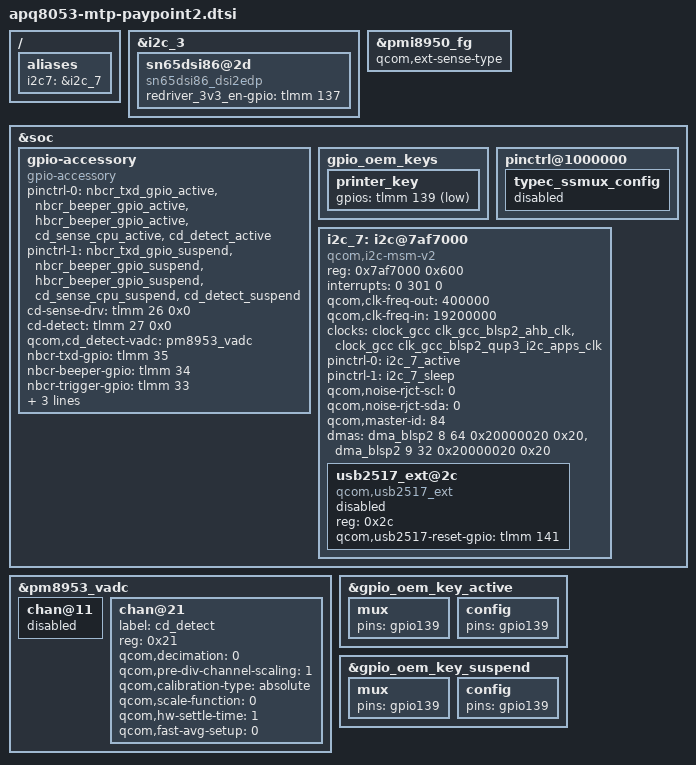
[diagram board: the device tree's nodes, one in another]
/*
 * Copyright (c) 2015-2016, The Linux Foundation. All rights reserved.
 *
 * This program is free software; you can redistribute it and/or modify
 * it under the terms of the GNU General Public License version 2 and
 * only version 2 as published by the Free Software Foundation.
 *
 * This program is distributed in the hope that it will be useful,
 * but WITHOUT ANY WARRANTY; without even the implied warranty of
 * MERCHANTABILITY or FITNESS FOR A PARTICULAR PURPOSE.  See the
 * GNU General Public License for more details.
 */
/ {
	aliases {
		i2c7 = &i2c_7;
	};
};

/*Leo Guo add for Puck to support HPD for DP panel*/
&i2c_3 {
	sn65dsi86@2d {
		compatible = "sn65dsi86_dsi2edp";
		redriver_3v3_en-gpio = <&tlmm 137 0>;
	};
};

&pmi8950_fg {
	/* use external rsense for parallel charging */
	qcom,ext-sense-type;
};


&soc {
	/*salyer add for peripheral */
	gpio-accessory{
		compatible = "gpio-accessory";
		pinctrl-names = "gpio_accessory_active","gpio_accessory_suspend";
		pinctrl-0 = <&nbcr_txd_gpio_active &nbcr_beeper_gpio_active &hbcr_beeper_gpio_active
				&cd_sense_cpu_active &cd_detect_active>;
		pinctrl-1 = <&nbcr_txd_gpio_suspend &nbcr_beeper_gpio_suspend &hbcr_beeper_gpio_suspend
 				&cd_sense_cpu_suspend &cd_detect_suspend>;

		/* Cash-Drawer GPIO */
		//cd-solenoid-en = <&tlmm 25 0x0>;
		cd-sense-drv = <&tlmm 26 0x0>;
		cd-detect = <&tlmm 27 0x0>;
		qcom,cd_detect-vadc = <&pm8953_vadc>;
		/* Cash-Drawer GPIO */

		/* Barcode reader GPIO */
		nbcr-txd-gpio = <&tlmm 35 0x0>;
		nbcr-beeper-gpio = <&tlmm 34 0x0>;
		nbcr-trigger-gpio = <&tlmm 33 0x0>;
		hbcr-beeper-gpio = <&tlmm 130 0x0>;
		hbcr-trigger-gpio = <&tlmm 131 0x0>;
		/* Barcode reader GPIO */

		/* enable printer 24v GPIO */
		pp-power-en = <&tlmm 28 0x0>;
		/* enable printer 24v GPIO */
		status = "okay";
	};

	/* 20170316, Adil.Zhu, moidify printer-key gpio for paypoint 2.0 */
	gpio_oem_keys {
		printer_key {
			gpios = <&tlmm 139 0x1>;
		};
	};

	pinctrl@1000000 {
		typec_ssmux_config {
			status = "disabled";
		};
	};

	/*2017-04-22 Jack W Lu: Add I2C_7 interface for external HUB2.0 SMBUS {*/
	i2c_7: i2c@7af7000 { /* BLSP2 QUP2 */
		compatible = "qcom,i2c-msm-v2";
		#address-cells = <1>;
		#size-cells = <0>;
		reg-names = "qup_phys_addr";
		reg = <0x7af7000 0x600>;
		interrupt-names = "qup_irq";
		interrupts = <0 301 0>;
		qcom,clk-freq-out = <400000>;
		qcom,clk-freq-in  = <19200000>;
		clock-names = "iface_clk", "core_clk";
		clocks = <&clock_gcc clk_gcc_blsp2_ahb_clk>,
			<&clock_gcc clk_gcc_blsp2_qup3_i2c_apps_clk>;

		pinctrl-names = "i2c_active", "i2c_sleep";
		pinctrl-0 = <&i2c_7_active>;
		pinctrl-1 = <&i2c_7_sleep>;
		qcom,noise-rjct-scl = <0>;
		qcom,noise-rjct-sda = <0>;
		qcom,master-id = <84>;
		dmas = <&dma_blsp2 8 64 0x20000020 0x20>,
			<&dma_blsp2 9 32 0x20000020 0x20>;
		dma-names = "tx", "rx";
		status = "okay";

		/*ONLY PP2.0 EVT2 use this setting*/
		usb2517_ext@2c {
			compatible = "qcom,usb2517_ext";
			reg = <0x2c>;
			qcom,usb2517-reset-gpio = <&tlmm 141 0>;/*Reserve_GPIO6: for external HUB2.0 usb2517 reset pin*/
			status = "disabled";/*ONLY PP2.0 EVT2 use this setting*/
		};
	};
	/*2017-04-22 Jack W Lu: Add I2C_7 interface for external HUB2.0 SMBUS }*/
};


&pm8953_vadc {
	chan@11 {
		status ="disabled";
	};

	/*pp,tony.l.cai,20170214,adc pin reserved for cd_detect{*/
	chan@21 {
		label = "cd_detect";
		reg = <0x21>;
		qcom,decimation = <0>;
		qcom,pre-div-channel-scaling = <1>; //1/3
		qcom,calibration-type = "absolute";
		qcom,scale-function = <0>;
		qcom,hw-settle-time = <1>; //1: Setting a delay of 100us is recommended for MPP channels.
		qcom,fast-avg-setup = <0>;
	};
	/*}pp,tony.l.cai,20170214,adc pin reserved for cd_detect*/
};

&gpio_oem_key_active{
    mux {
            pins = "gpio139";
        };

    config {
            pins =  "gpio139";
        };
};

&gpio_oem_key_suspend {
    mux {
            pins = "gpio139";
        };

    config {
            pins ="gpio139";
        };
};
